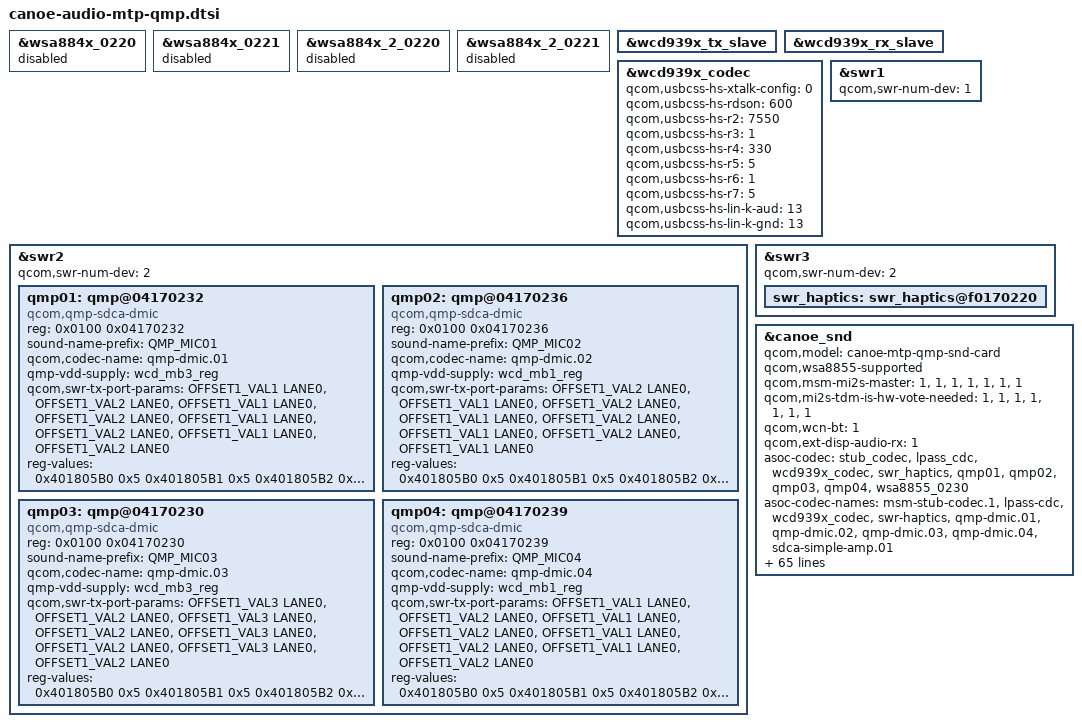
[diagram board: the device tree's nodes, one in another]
//
/* Copyright (c) Qualcomm Technologies, Inc. and/or its subsidiaries.
 *  SPDX-License-Identifier: BSD-3-Clause-Clear
 */

#include "lpass-audio-cdc-1.0.dtsi"
#include "canoe-lpi.dtsi"
#include "lpass-audio-bt-swr.dtsi"
#include "lpass-cdc-gpio.dtsi"
#include "canoe-audio-lpass-reg.dtsi"
#include "wsa884x.dtsi"
#include "wcd939x.dtsi"
#include "canoe-audio-simple-amp.dtsi"

&wsa884x_0220 {
	status = "disabled";
};

&wsa884x_0221 {
	status = "disabled";
};

&wsa884x_2_0220 {
	status = "disabled";
};

&wsa884x_2_0221 {
	status = "disabled";
};

&wcd939x_tx_slave {
	status = "okay";
};

&wcd939x_rx_slave {
	status = "okay";
};

&wcd939x_codec {
	status = "okay";
	/* 0 for digital crosstalk disabled,
	 * 1 for digital crosstalk with local sensed a-xtalk enabled, and
	 * 2 for digital crosstalk with remote sensed a-xtalk enabled.
	 */
	qcom,usbcss-hs-xtalk-config = <0>;
	qcom,usbcss-hs-rdson = <600>;
	qcom,usbcss-hs-r2 = <7550>;
	qcom,usbcss-hs-r3 = <1>;
	qcom,usbcss-hs-r4 = <330>;
	qcom,usbcss-hs-r5 = <5>;
	qcom,usbcss-hs-r6 = <1>;
	qcom,usbcss-hs-r7 = <5>;
	qcom,usbcss-hs-lin-k-aud = <13>;
	qcom,usbcss-hs-lin-k-gnd = <13>;

};

&swr1 {
	qcom,swr-num-dev = <1>;
};

&swr2 {
	qcom,swr-num-dev = <2>;
};

&swr3 {
	qcom,swr-num-dev = <2>;
	swr_haptics: swr_haptics@f0170220 {
		status = "okay";
	};
};

&swr2 {
	qmp01: qmp@04170232 {
		/*
		 * reg = <Class_partID[7:0]
		 * partID[15:8] manuID[7:0] manuID[15:8](version4bits_UniqueID4bits)
		 */
		reg = <0x0100 0x04170232>;
		compatible = "qcom,qmp-sdca-dmic";
		sound-name-prefix = "QMP_MIC01";
		qcom,codec-name = "qmp-dmic.01";
		qmp-vdd-supply = <&wcd_mb3_reg>;
		qcom,swr-tx-port-params =
				<OFFSET1_VAL1 LANE0>, <OFFSET1_VAL2 LANE0>,
				<OFFSET1_VAL1 LANE0>, <OFFSET1_VAL2 LANE0>,
				<OFFSET1_VAL1 LANE0>, <OFFSET1_VAL2 LANE0>,
				<OFFSET1_VAL1 LANE0>, <OFFSET1_VAL2 LANE0>;
		reg-values = <0x401805B0 0x5
				  0x401805B1 0x5
				  0x401805B2 0x5
				  0x401805B3 0x5
				  0x401805B8 0x5>;
	};

	qmp02: qmp@04170236 {
		reg = <0x0100 0x04170236>;
		compatible = "qcom,qmp-sdca-dmic";
		sound-name-prefix = "QMP_MIC02";
		qcom,codec-name = "qmp-dmic.02";
		qmp-vdd-supply = <&wcd_mb1_reg>;
		qcom,swr-tx-port-params =
				<OFFSET1_VAL2 LANE0>, <OFFSET1_VAL1 LANE0>,
				<OFFSET1_VAL2 LANE0>, <OFFSET1_VAL1 LANE0>,
				<OFFSET1_VAL2 LANE0>, <OFFSET1_VAL1 LANE0>,
				<OFFSET1_VAL2 LANE0>, <OFFSET1_VAL1 LANE0>;
		reg-values = <0x401805B0 0x5
				  0x401805B1 0x5
				  0x401805B2 0x5
				  0x401805B3 0x5
				  0x401805B8 0x5>;
	};

	qmp03: qmp@04170230 {
		reg = <0x0100 0x04170230>;
		compatible = "qcom,qmp-sdca-dmic";
		sound-name-prefix = "QMP_MIC03";
		qcom,codec-name = "qmp-dmic.03";
		qmp-vdd-supply = <&wcd_mb3_reg>;
		qcom,swr-tx-port-params =
				<OFFSET1_VAL3 LANE0>, <OFFSET1_VAL2 LANE0>,
				<OFFSET1_VAL3 LANE0>, <OFFSET1_VAL2 LANE0>,
				<OFFSET1_VAL3 LANE0>, <OFFSET1_VAL2 LANE0>,
				<OFFSET1_VAL3 LANE0>, <OFFSET1_VAL2 LANE0>;
		reg-values = <0x401805B0 0x5
				  0x401805B1 0x5
				  0x401805B2 0x5
				  0x401805B3 0x5
				  0x401805B8 0x5>;
	};

	qmp04: qmp@04170239 {
		reg = <0x0100 0x04170239>;
		compatible = "qcom,qmp-sdca-dmic";
		sound-name-prefix = "QMP_MIC04";
		qcom,codec-name = "qmp-dmic.04";
		qmp-vdd-supply = <&wcd_mb1_reg>;
		qcom,swr-tx-port-params =
				<OFFSET1_VAL1 LANE0>, <OFFSET1_VAL2 LANE0>,
				<OFFSET1_VAL1 LANE0>, <OFFSET1_VAL2 LANE0>,
				<OFFSET1_VAL1 LANE0>, <OFFSET1_VAL2 LANE0>,
				<OFFSET1_VAL1 LANE0>, <OFFSET1_VAL2 LANE0>;
		reg-values = <0x401805B0 0x5
				  0x401805B1 0x5
				  0x401805B2 0x5
				  0x401805B3 0x5
				  0x401805B8 0x5>;
	};
};

&canoe_snd {
	qcom,model = "canoe-mtp-qmp-snd-card";
	qcom,wsa8855-supported;
	qcom,msm-mi2s-master = <1>, <1>, <1>, <1>, <1>, <1>, <1>;
	qcom,mi2s-tdm-is-hw-vote-needed = <1>, <1>, <1>, <1>, <1>, <1>, <1>;
	qcom,wcn-bt = <1>;
	qcom,ext-disp-audio-rx = <1>;
	asoc-codec  = <&stub_codec>, <&lpass_cdc>,
			<&wcd939x_codec>, <&swr_haptics>,
			<&qmp01>, <&qmp02>,
			<&qmp03>, <&qmp04>, <&wsa8855_0230>;
	asoc-codec-names = "msm-stub-codec.1", "lpass-cdc",
		"wcd939x_codec", "swr-haptics",
		"qmp-dmic.01", "qmp-dmic.02",
		"qmp-dmic.03", "qmp-dmic.04", "sdca-simple-amp.01";
	qcom,qmp-mic = <1>;
	qcom,tdm-max-slots = <8>;
	qcom,tdm-clk-attribute = <0x1>, <0x1>, <0x1>, <0x1>, <0x1>, <0x1>, <0x1>;
	qcom,mi2s-clk-attribute = <0x1>, <0x1>, <0x1>, <0x1>, <0x1>, <0x1>, <0x1>;
	qcom,audio-core-list = <0>, <1>;
	qcom,audio-routing =
		"AMIC1", "Analog Mic1",
		"AMIC1", "MIC BIAS1",
		"AMIC2", "Analog Mic2",
		"AMIC2", "MIC BIAS2",
		"AMIC3", "Analog Mic3",
		"AMIC3", "MIC BIAS3",
		"AMIC4", "Analog Mic4",
		"AMIC4", "MIC BIAS3",
		"AMIC5", "Analog Mic5",
		"AMIC5", "MIC BIAS4",
		"VA AMIC1", "Analog Mic1",
		"VA AMIC1", "VA MIC BIAS1",
		"VA AMIC2", "Analog Mic2",
		"VA AMIC2", "VA MIC BIAS2",
		"VA AMIC3", "Analog Mic3",
		"VA AMIC3", "VA MIC BIAS3",
		"VA AMIC4", "Analog Mic4",
		"VA AMIC4", "VA MIC BIAS3",
		"VA AMIC5", "Analog Mic5",
		"VA AMIC5", "VA MIC BIAS4",
		"TX DMIC0", "Digital Mic0",
		"TX DMIC0", "MIC BIAS1",
		"TX DMIC1", "Digital Mic1",
		"TX DMIC1", "MIC BIAS3",
		"TX DMIC2", "Digital Mic2",
		"TX DMIC2", "MIC BIAS3",
		"TX DMIC3", "Digital Mic3",
		"TX DMIC3", "MIC BIAS1",
		"IN1_HPHL", "HPHL_OUT",
		"IN2_HPHR", "HPHR_OUT",
		"IN3_EAR", "AUX_OUT",
		"HAP_IN", "WSA2_HAPT OUT",
		"WSA SRC0_INP", "SRC0",
		"WSA_TX DEC0_INP", "TX DEC0 MUX",
		"WSA_TX DEC1_INP", "TX DEC1 MUX",
		"RX_TX DEC0_INP", "TX DEC0 MUX",
		"RX_TX DEC1_INP", "TX DEC1 MUX",
		"RX_TX DEC2_INP", "TX DEC2 MUX",
		"RX_TX DEC3_INP", "TX DEC3 MUX",
		"SA1 AMP IN", "WSA_SPK1 OUT",
		"SA1 AMP IN", "WSA_SPK2 OUT",
		"TX SWR_INPUT", "WCD_TX_OUTPUT",
		"TX SWR_INPUT", "QMP_MIC01 NORMAL_OUTPUT",
		"TX SWR_INPUT", "QMP_MIC02 NORMAL_OUTPUT",
		"TX SWR_INPUT", "QMP_MIC03 NORMAL_OUTPUT",
		"TX SWR_INPUT", "QMP_MIC04 NORMAL_OUTPUT",
		"VA SWR_INPUT", "VA_SWR_CLK",
		"VA SWR_INPUT", "WCD_TX_OUTPUT",
		"VA SWR_INPUT", "QMP_MIC01 LP_OUTPUT",
		"VA SWR_INPUT", "QMP_MIC02 LP_OUTPUT",
		"VA SWR_INPUT", "QMP_MIC03 LP_OUTPUT",
		"VA SWR_INPUT", "QMP_MIC04 LP_OUTPUT",
		"VA SWR_INPUT", "QMP_MIC01 VA_NORMAL_OUTPUT",
		"VA SWR_INPUT", "QMP_MIC02 VA_NORMAL_OUTPUT",
		"VA SWR_INPUT", "QMP_MIC03 VA_NORMAL_OUTPUT",
		"VA SWR_INPUT", "QMP_MIC04 VA_NORMAL_OUTPUT",
		"VA_AIF1 CAP", "VA_SWR_CLK",
		"VA_AIF2 CAP", "VA_SWR_CLK",
		"VA_AIF3 CAP", "VA_SWR_CLK",
		"VA DMIC0", "Digital Mic0",
		"VA DMIC1", "Digital Mic1",
		"VA DMIC2", "Digital Mic2",
		"VA DMIC3", "Digital Mic3",
		"VA DMIC0", "VA MIC BIAS3",
		"VA DMIC1", "VA MIC BIAS3",
		"VA DMIC2", "VA MIC BIAS1",
		"VA DMIC3", "VA MIC BIAS1";
	qcom,wsa-max-devs = <1>;
	qcom,msm-mbhc-hs-mic-max-threshold-mv = <1670>;
	qcom,msm-mbhc-usbc-audio-supported = <1>;
	qcom,msm-mbhc-hphl-swh = <0>;
	qcom,msm-mbhc-gnd-swh = <0>;
	wcd939x-i2c-handle = <&wcd_usbss>;
	qcom,msm_audio_ssr_devs = <&audio_gpr>, <&lpi_tlmm>,
				  <&lpass_cdc>, <&lpass_bt_swr>;
	/*
	 * Add this property,
	 * To Enable swr haptics through OPCM port.
	 * This will include wsa2 dailinks.
	 */
	qcom,dedicated-wsa2;
	/*
	 * ====================
	 * UPD backend - WSA
	 * ====================
	 *
	 * Mute/Unmute the interpolator
	 * ------------------------------
	 * Register:Â LPASS_WSA_CDC_RX0_RX_PATH_MIX_CTL - 0x6B00418
	 *
	 * Send control commands to the peripheral from the soundwire controller
	 * -----------------------------------------------------------------------
	 * Register: LPASS_WSA_SWR_MSTR_WSA_SWRM_CPUn_CMD_FIFO_WR_CMD - 0x6B14020
	 *
	 * Enable/Disable ear piece
	 * --------------------------
	 * Register:Â DIG_CTRL0_PA_FSM_EN - 0x3430
	 *
	 */
	qcom,upd_backends_used = "wsa";
	qcom,upd_lpass_reg_addr = <0x6B00418 0x6B14020>;
	qcom,upd_ear_pa_reg_addr = <0x3430>;
};
